VERSION "c2g-draft-1"

NS_ :

BS_:

BU_: MAXXECU

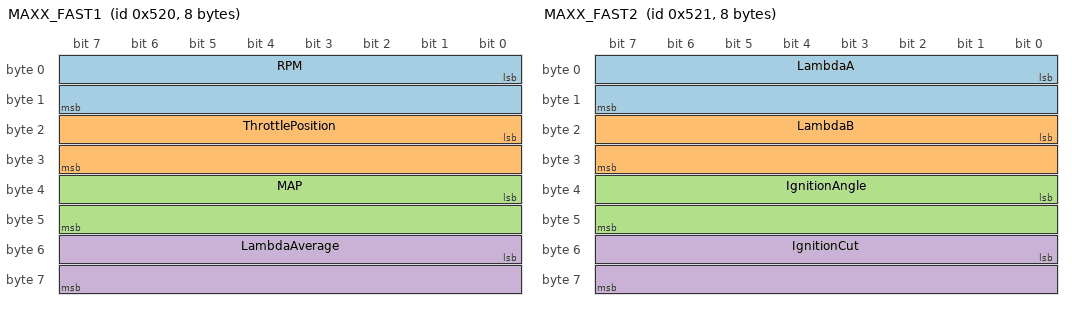
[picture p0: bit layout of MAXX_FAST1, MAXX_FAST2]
BO_ 1312 MAXX_FAST1: 8 MAXXECU
 SG_ RPM : 0|16@1- (1,0) [-32768|32767] "rpm" Vector__XXX
 SG_ ThrottlePosition : 16|16@1- (0.1,0) [-3276.8|3276.7] "%" Vector__XXX
 SG_ MAP : 32|16@1- (0.1,0) [-3276.8|3276.7] "kPa" Vector__XXX
 SG_ LambdaAverage : 48|16@1- (0.001,0) [-32.768|32.767] "lambda" Vector__XXX

BO_ 1313 MAXX_FAST2: 8 MAXXECU
 SG_ LambdaA : 0|16@1- (0.001,0) [-32.768|32.767] "lambda" Vector__XXX
 SG_ LambdaB : 16|16@1- (0.001,0) [-32.768|32.767] "lambda" Vector__XXX
 SG_ IgnitionAngle : 32|16@1- (0.1,0) [-3276.8|3276.7] "deg" Vector__XXX
 SG_ IgnitionCut : 48|16@1- (1,0) [-32768|32767] "%" Vector__XXX

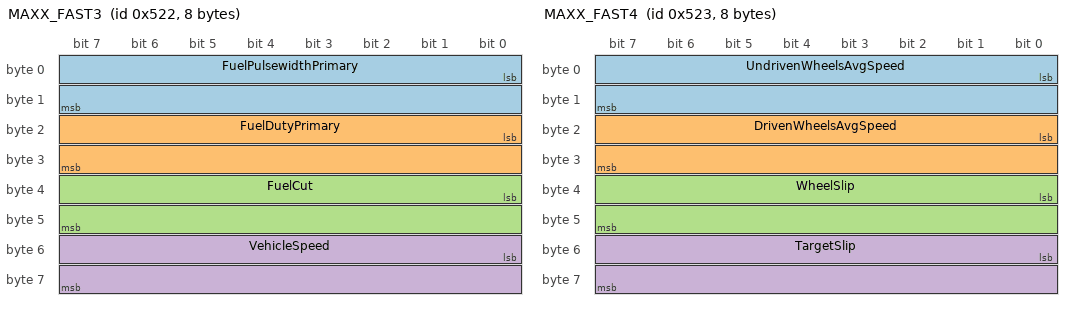
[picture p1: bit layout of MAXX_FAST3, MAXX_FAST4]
BO_ 1314 MAXX_FAST3: 8 MAXXECU
 SG_ FuelPulsewidthPrimary : 0|16@1- (0.01,0) [-327.68|327.67] "ms" Vector__XXX
 SG_ FuelDutyPrimary : 16|16@1- (0.1,0) [-3276.8|3276.7] "%" Vector__XXX
 SG_ FuelCut : 32|16@1- (1,0) [-32768|32767] "%" Vector__XXX
 SG_ VehicleSpeed : 48|16@1- (0.1,0) [-3276.8|3276.7] "km/h" Vector__XXX

BO_ 1315 MAXX_FAST4: 8 MAXXECU
 SG_ UndrivenWheelsAvgSpeed : 0|16@1- (0.1,0) [-3276.8|3276.7] "km/h" Vector__XXX
 SG_ DrivenWheelsAvgSpeed : 16|16@1- (0.1,0) [-3276.8|3276.7] "km/h" Vector__XXX
 SG_ WheelSlip : 32|16@1- (0.1,0) [-3276.8|3276.7] "%" Vector__XXX
 SG_ TargetSlip : 48|16@1- (0.1,0) [-3276.8|3276.7] "%" Vector__XXX

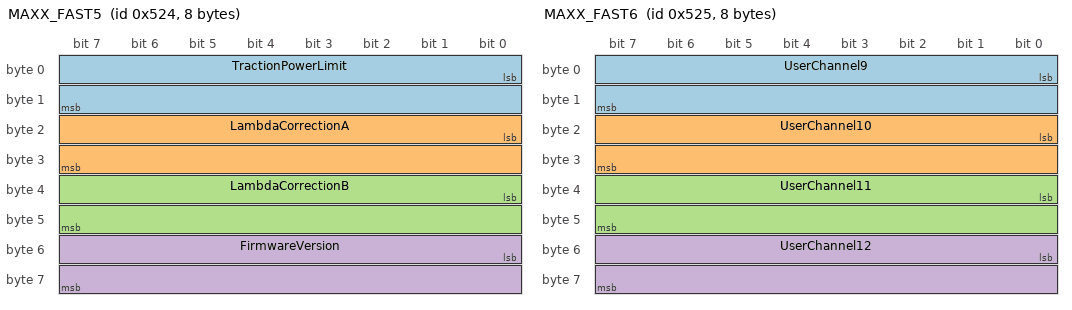
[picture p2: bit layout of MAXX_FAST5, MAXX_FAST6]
BO_ 1316 MAXX_FAST5: 8 MAXXECU
 SG_ TractionPowerLimit : 0|16@1- (0.1,0) [-3276.8|3276.7] "%" Vector__XXX
 SG_ LambdaCorrectionA : 16|16@1- (0.1,0) [-3276.8|3276.7] "%" Vector__XXX
 SG_ LambdaCorrectionB : 32|16@1- (0.1,0) [-3276.8|3276.7] "%" Vector__XXX
 SG_ FirmwareVersion : 48|16@1- (0.001,0) [-32.768|32.767] "" Vector__XXX

BO_ 1317 MAXX_FAST6: 8 MAXXECU
 SG_ UserChannel9 : 0|16@1- (0.1,0) [-3276.8|3276.7] "" Vector__XXX
 SG_ UserChannel10 : 16|16@1- (0.1,0) [-3276.8|3276.7] "" Vector__XXX
 SG_ UserChannel11 : 32|16@1- (0.1,0) [-3276.8|3276.7] "" Vector__XXX
 SG_ UserChannel12 : 48|16@1- (0.1,0) [-3276.8|3276.7] "" Vector__XXX

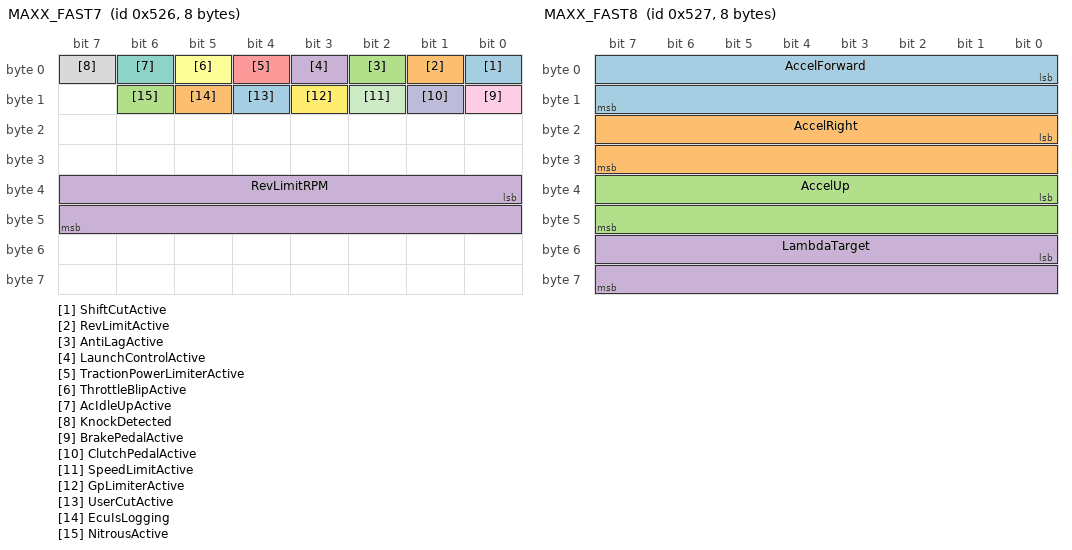
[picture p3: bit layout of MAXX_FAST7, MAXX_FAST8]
BO_ 1318 MAXX_FAST7: 8 MAXXECU
 SG_ ShiftCutActive : 0|1@1+ (1,0) [0|1] "" Vector__XXX
 SG_ RevLimitActive : 1|1@1+ (1,0) [0|1] "" Vector__XXX
 SG_ AntiLagActive : 2|1@1+ (1,0) [0|1] "" Vector__XXX
 SG_ LaunchControlActive : 3|1@1+ (1,0) [0|1] "" Vector__XXX
 SG_ TractionPowerLimiterActive : 4|1@1+ (1,0) [0|1] "" Vector__XXX
 SG_ ThrottleBlipActive : 5|1@1+ (1,0) [0|1] "" Vector__XXX
 SG_ AcIdleUpActive : 6|1@1+ (1,0) [0|1] "" Vector__XXX
 SG_ KnockDetected : 7|1@1+ (1,0) [0|1] "" Vector__XXX
 SG_ BrakePedalActive : 8|1@1+ (1,0) [0|1] "" Vector__XXX
 SG_ ClutchPedalActive : 9|1@1+ (1,0) [0|1] "" Vector__XXX
 SG_ SpeedLimitActive : 10|1@1+ (1,0) [0|1] "" Vector__XXX
 SG_ GpLimiterActive : 11|1@1+ (1,0) [0|1] "" Vector__XXX
 SG_ UserCutActive : 12|1@1+ (1,0) [0|1] "" Vector__XXX
 SG_ EcuIsLogging : 13|1@1+ (1,0) [0|1] "" Vector__XXX
 SG_ NitrousActive : 14|1@1+ (1,0) [0|1] "" Vector__XXX
 SG_ RevLimitRPM : 32|16@1- (1,0) [-32768|32767] "rpm" Vector__XXX

BO_ 1319 MAXX_FAST8: 8 MAXXECU
 SG_ AccelForward : 0|16@1- (0.01,0) [-327.68|327.67] "G" Vector__XXX
 SG_ AccelRight : 16|16@1- (0.01,0) [-327.68|327.67] "G" Vector__XXX
 SG_ AccelUp : 32|16@1- (0.01,0) [-327.68|327.67] "G" Vector__XXX
 SG_ LambdaTarget : 48|16@1- (0.001,0) [-32.768|32.767] "lambda" Vector__XXX

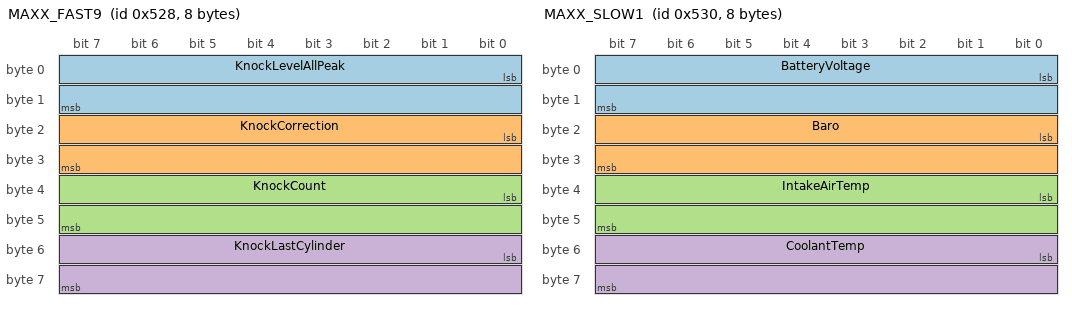
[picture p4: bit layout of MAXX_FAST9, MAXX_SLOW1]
BO_ 1320 MAXX_FAST9: 8 MAXXECU
 SG_ KnockLevelAllPeak : 0|16@1- (1,0) [-32768|32767] "" Vector__XXX
 SG_ KnockCorrection : 16|16@1- (0.1,0) [-3276.8|3276.7] "deg" Vector__XXX
 SG_ KnockCount : 32|16@1- (1,0) [-32768|32767] "" Vector__XXX
 SG_ KnockLastCylinder : 48|16@1- (1,0) [-32768|32767] "" Vector__XXX

BO_ 1328 MAXX_SLOW1: 8 MAXXECU
 SG_ BatteryVoltage : 0|16@1- (0.01,0) [-327.68|327.67] "V" Vector__XXX
 SG_ Baro : 16|16@1- (0.1,0) [-3276.8|3276.7] "kPa" Vector__XXX
 SG_ IntakeAirTemp : 32|16@1- (0.1,0) [-3276.8|3276.7] "C" Vector__XXX
 SG_ CoolantTemp : 48|16@1- (0.1,0) [-3276.8|3276.7] "C" Vector__XXX

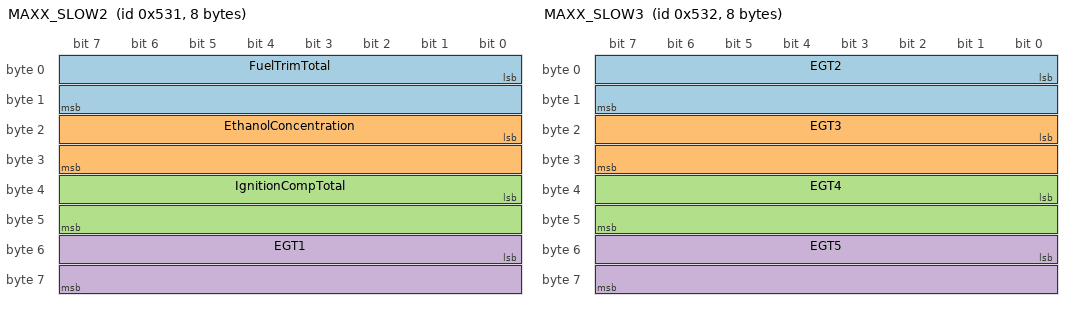
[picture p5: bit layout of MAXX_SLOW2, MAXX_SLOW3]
BO_ 1329 MAXX_SLOW2: 8 MAXXECU
 SG_ FuelTrimTotal : 0|16@1- (0.1,0) [-3276.8|3276.7] "%" Vector__XXX
 SG_ EthanolConcentration : 16|16@1- (0.1,0) [-3276.8|3276.7] "%" Vector__XXX
 SG_ IgnitionCompTotal : 32|16@1- (0.1,0) [-3276.8|3276.7] "deg" Vector__XXX
 SG_ EGT1 : 48|16@1- (1,0) [-32768|32767] "C" Vector__XXX

BO_ 1330 MAXX_SLOW3: 8 MAXXECU
 SG_ EGT2 : 0|16@1- (1,0) [-32768|32767] "C" Vector__XXX
 SG_ EGT3 : 16|16@1- (1,0) [-32768|32767] "C" Vector__XXX
 SG_ EGT4 : 32|16@1- (1,0) [-32768|32767] "C" Vector__XXX
 SG_ EGT5 : 48|16@1- (1,0) [-32768|32767] "C" Vector__XXX

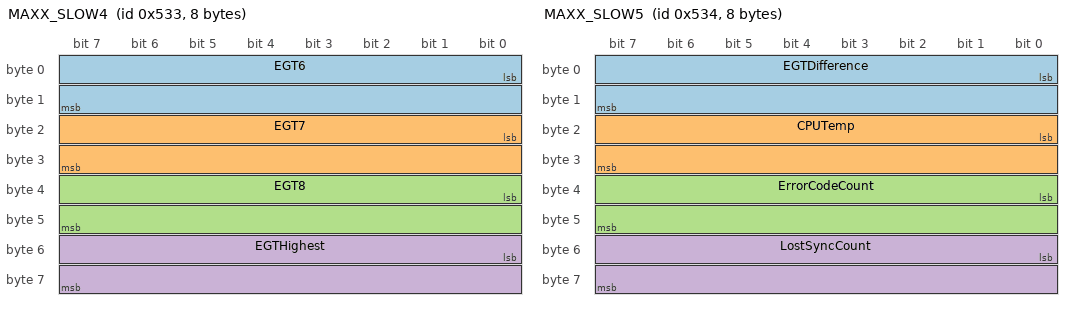
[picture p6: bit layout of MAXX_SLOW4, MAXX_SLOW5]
BO_ 1331 MAXX_SLOW4: 8 MAXXECU
 SG_ EGT6 : 0|16@1- (1,0) [-32768|32767] "C" Vector__XXX
 SG_ EGT7 : 16|16@1- (1,0) [-32768|32767] "C" Vector__XXX
 SG_ EGT8 : 32|16@1- (1,0) [-32768|32767] "C" Vector__XXX
 SG_ EGTHighest : 48|16@1- (1,0) [-32768|32767] "C" Vector__XXX

BO_ 1332 MAXX_SLOW5: 8 MAXXECU
 SG_ EGTDifference : 0|16@1- (1,0) [-32768|32767] "C" Vector__XXX
 SG_ CPUTemp : 16|16@1- (1,0) [-32768|32767] "C" Vector__XXX
 SG_ ErrorCodeCount : 32|16@1- (1,0) [-32768|32767] "" Vector__XXX
 SG_ LostSyncCount : 48|16@1- (1,0) [-32768|32767] "" Vector__XXX

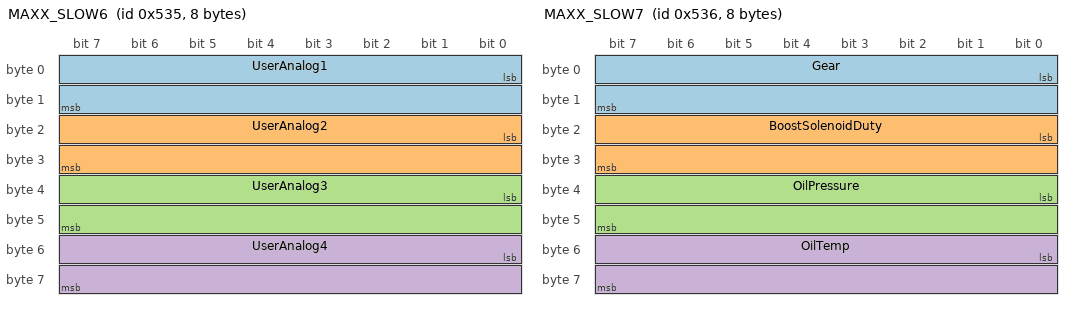
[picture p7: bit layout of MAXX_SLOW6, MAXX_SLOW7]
BO_ 1333 MAXX_SLOW6: 8 MAXXECU
 SG_ UserAnalog1 : 0|16@1- (0.1,0) [-3276.8|3276.7] "" Vector__XXX
 SG_ UserAnalog2 : 16|16@1- (0.1,0) [-3276.8|3276.7] "" Vector__XXX
 SG_ UserAnalog3 : 32|16@1- (0.1,0) [-3276.8|3276.7] "" Vector__XXX
 SG_ UserAnalog4 : 48|16@1- (0.1,0) [-3276.8|3276.7] "" Vector__XXX

BO_ 1334 MAXX_SLOW7: 8 MAXXECU
 SG_ Gear : 0|16@1- (1,0) [-32768|32767] "" Vector__XXX
 SG_ BoostSolenoidDuty : 16|16@1- (0.1,0) [-3276.8|3276.7] "%" Vector__XXX
 SG_ OilPressure : 32|16@1- (0.1,0) [-3276.8|3276.7] "kPa" Vector__XXX
 SG_ OilTemp : 48|16@1- (0.1,0) [-3276.8|3276.7] "C" Vector__XXX

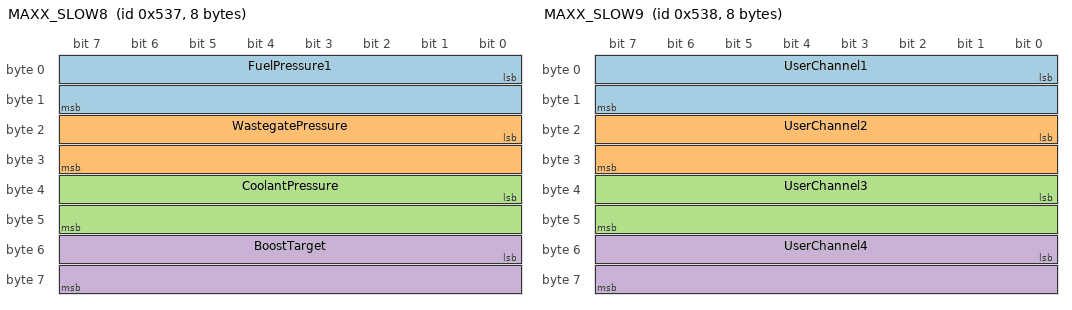
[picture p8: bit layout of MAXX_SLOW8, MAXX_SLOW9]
BO_ 1335 MAXX_SLOW8: 8 MAXXECU
 SG_ FuelPressure1 : 0|16@1- (0.1,0) [-3276.8|3276.7] "kPa" Vector__XXX
 SG_ WastegatePressure : 16|16@1- (0.1,0) [-3276.8|3276.7] "kPa" Vector__XXX
 SG_ CoolantPressure : 32|16@1- (0.1,0) [-3276.8|3276.7] "kPa" Vector__XXX
 SG_ BoostTarget : 48|16@1- (0.1,0) [-3276.8|3276.7] "kPa" Vector__XXX

BO_ 1336 MAXX_SLOW9: 8 MAXXECU
 SG_ UserChannel1 : 0|16@1- (0.1,0) [-3276.8|3276.7] "" Vector__XXX
 SG_ UserChannel2 : 16|16@1- (0.1,0) [-3276.8|3276.7] "" Vector__XXX
 SG_ UserChannel3 : 32|16@1- (0.1,0) [-3276.8|3276.7] "" Vector__XXX
 SG_ UserChannel4 : 48|16@1- (0.1,0) [-3276.8|3276.7] "" Vector__XXX

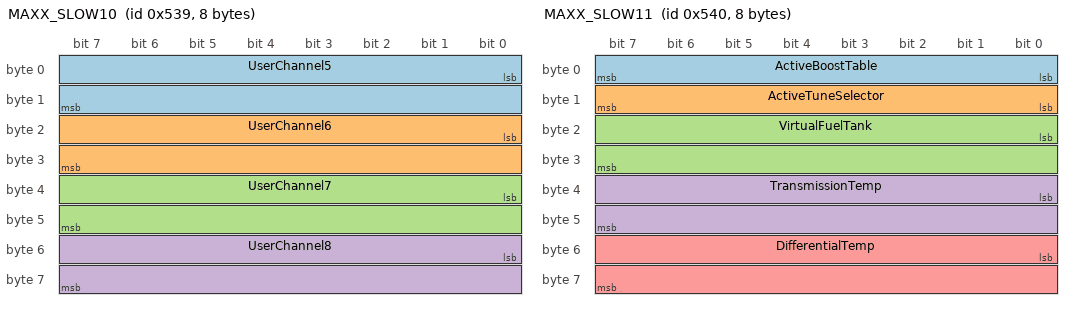
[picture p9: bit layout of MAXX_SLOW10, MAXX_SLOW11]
BO_ 1337 MAXX_SLOW10: 8 MAXXECU
 SG_ UserChannel5 : 0|16@1- (0.1,0) [-3276.8|3276.7] "" Vector__XXX
 SG_ UserChannel6 : 16|16@1- (0.1,0) [-3276.8|3276.7] "" Vector__XXX
 SG_ UserChannel7 : 32|16@1- (0.1,0) [-3276.8|3276.7] "" Vector__XXX
 SG_ UserChannel8 : 48|16@1- (0.1,0) [-3276.8|3276.7] "" Vector__XXX

BO_ 1344 MAXX_SLOW11: 8 MAXXECU
 SG_ ActiveBoostTable : 0|8@1+ (1,0) [0|255] "" Vector__XXX
 SG_ ActiveTuneSelector : 8|8@1+ (1,0) [0|255] "" Vector__XXX
 SG_ VirtualFuelTank : 16|16@1- (0.1,0) [-3276.8|3276.7] "L" Vector__XXX
 SG_ TransmissionTemp : 32|16@1- (0.1,0) [-3276.8|3276.7] "C" Vector__XXX
 SG_ DifferentialTemp : 48|16@1- (0.1,0) [-3276.8|3276.7] "C" Vector__XXX

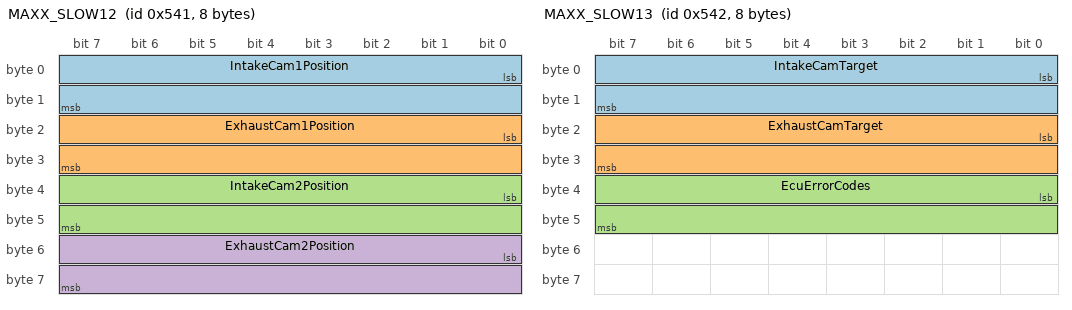
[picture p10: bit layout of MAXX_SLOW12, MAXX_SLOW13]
BO_ 1345 MAXX_SLOW12: 8 MAXXECU
 SG_ IntakeCam1Position : 0|16@1- (0.1,0) [-3276.8|3276.7] "deg" Vector__XXX
 SG_ ExhaustCam1Position : 16|16@1- (0.1,0) [-3276.8|3276.7] "deg" Vector__XXX
 SG_ IntakeCam2Position : 32|16@1- (0.1,0) [-3276.8|3276.7] "deg" Vector__XXX
 SG_ ExhaustCam2Position : 48|16@1- (0.1,0) [-3276.8|3276.7] "deg" Vector__XXX

BO_ 1346 MAXX_SLOW13: 8 MAXXECU
 SG_ IntakeCamTarget : 0|16@1- (0.1,0) [-3276.8|3276.7] "deg" Vector__XXX
 SG_ ExhaustCamTarget : 16|16@1- (0.1,0) [-3276.8|3276.7] "deg" Vector__XXX
 SG_ EcuErrorCodes : 32|16@1+ (1,0) [0|65535] "" Vector__XXX

CM_ "DRAFT can2gauge DBC: MaxxECU Default CAN protocol 1.2 + 1.3 (base 0x520, movable with 'DefaultCANProtocol ID Offset', fw 1.149+). Written from the published webhelp layout; MaxxECU's own DBC (TT-Speed, no licence stated) was only read for cross-checking. All values int16 per the webhelp.";
CM_ BO_ 1312 "Source: maxxecu.com webhelp can-default_maxxecu_protocol. v1.2.";
CM_ SG_ 1312 MAP "Absolute kPa (gauge 'map' is mbar: x10). Boost = MAP - baro (0x530) stays in code.";
CM_ BO_ 1313 "Source: maxxecu.com webhelp can-default_maxxecu_protocol. v1.2.";
CM_ BO_ 1314 "Source: maxxecu.com webhelp can-default_maxxecu_protocol. v1.2.";
CM_ BO_ 1315 "Source: maxxecu.com webhelp can-default_maxxecu_protocol. v1.2.";
CM_ BO_ 1316 "Source: maxxecu.com webhelp can-default_maxxecu_protocol. v1.2.";
CM_ SG_ 1316 FirmwareVersion "Webhelp scale 0.001; MaxxECU's own v1.3 DBC says 0.01 - UNVERIFIED which. Constant while running: useful fingerprint.";
CM_ BO_ 1317 "Source: maxxecu.com webhelp can-default_maxxecu_protocol. v1.3, fw 1.135+.";
CM_ BO_ 1318 "Source: maxxecu.com webhelp can-default_maxxecu_protocol. v1.3, fw 1.135+.";
CM_ SG_ 1318 KnockDetected "Held 250 ms after a knock (MaxxECU DBC comment).";
CM_ BO_ 1319 "Source: maxxecu.com webhelp can-default_maxxecu_protocol. v1.3, fw 1.135+.";
CM_ BO_ 1320 "Source: maxxecu.com webhelp can-default_maxxecu_protocol. v1.3, fw 1.135+.";
CM_ SG_ 1320 KnockCorrection "Sign convention (retard positive or negative) not stated - UNVERIFIED.";
CM_ BO_ 1328 "Source: maxxecu.com webhelp can-default_maxxecu_protocol. v1.2.";
CM_ SG_ 1328 Baro "Fingerprint: raw ~950-1050 at sea level.";
CM_ BO_ 1329 "Source: maxxecu.com webhelp can-default_maxxecu_protocol. v1.2.";
CM_ SG_ 1329 EthanolConcentration "Webhelp: outputs 85 % with no sensor or a sensor error. MaxxECU's own DBC comment says zero - UNVERIFIED which (firmware dependent?).";
CM_ SG_ 1329 EGT1 "All EGTs are sent even for unconfigured sensors.";
CM_ BO_ 1330 "Source: maxxecu.com webhelp can-default_maxxecu_protocol. v1.2.";
CM_ BO_ 1331 "Source: maxxecu.com webhelp can-default_maxxecu_protocol. v1.2.";
CM_ BO_ 1332 "Source: maxxecu.com webhelp can-default_maxxecu_protocol. v1.2.";
CM_ BO_ 1333 "Source: maxxecu.com webhelp can-default_maxxecu_protocol. v1.2, fw 1.79+.";
CM_ BO_ 1334 "Source: maxxecu.com webhelp can-default_maxxecu_protocol. Bytes 0-3 v1.2 (fw 1.79+), bytes 4-7 v1.3 (fw 1.135+; nothing sent there in 1.2).";
CM_ SG_ 1334 Gear "Encoding of reverse / neutral not documented - UNVERIFIED (0 assumed neutral).";
CM_ SG_ 1334 BoostSolenoidDuty "Webhelp table says v1.2; its changelog says 0x536 bytes 2-3 were spare in 1.2 - UNVERIFIED.";
CM_ SG_ 1334 OilPressure "kPa (gauge 'oilPressure' is bar: /100). Absolute or gauge not stated - UNVERIFIED.";
CM_ BO_ 1335 "Source: maxxecu.com webhelp can-default_maxxecu_protocol. v1.3, fw 1.135+.";
CM_ SG_ 1335 FuelPressure1 "kPa (gauge 'fuelPressure' is bar: /100). Absolute or gauge not stated - UNVERIFIED.";
CM_ BO_ 1336 "Source: maxxecu.com webhelp can-default_maxxecu_protocol. v1.3, fw 1.135+.";
CM_ BO_ 1337 "Source: maxxecu.com webhelp can-default_maxxecu_protocol. v1.3, fw 1.135+.";
CM_ BO_ 1344 "Source: maxxecu.com webhelp can-default_maxxecu_protocol. v1.3, fw 1.135+. MaxxECU warns 0x540 collides with VAG DSG: use 1.2 (or move the offset) on DSG cars.";
CM_ BO_ 1345 "Source: maxxecu.com webhelp can-default_maxxecu_protocol. v1.3, fw 1.135+.";
CM_ BO_ 1346 "Source: maxxecu.com webhelp can-default_maxxecu_protocol. v1.3, fw 1.135+.";
CM_ SG_ 1346 EcuErrorCodes "uint16, fw 1.149+, rotates through stored codes, 0x0000 = none.";
BA_DEF_ SG_ "GaugeKey" STRING ;
BA_DEF_ "GaugeRelocatable" INT 0 1;
BA_DEF_ "GaugeBusSpeed" INT 0 1000000;
BA_DEF_ BO_ "GenMsgCycleTime" INT 0 65535;
BA_DEF_DEF_ "GaugeKey" "";
BA_DEF_DEF_ "GaugeRelocatable" 0;
BA_DEF_DEF_ "GaugeBusSpeed" 500000;
BA_DEF_DEF_ "GenMsgCycleTime" 0;
BA_ "GaugeRelocatable" 1;
BA_ "GenMsgCycleTime" BO_ 1312 20;
BA_ "GenMsgCycleTime" BO_ 1313 20;
BA_ "GenMsgCycleTime" BO_ 1314 20;
BA_ "GenMsgCycleTime" BO_ 1315 20;
BA_ "GenMsgCycleTime" BO_ 1316 20;
BA_ "GenMsgCycleTime" BO_ 1317 20;
BA_ "GenMsgCycleTime" BO_ 1318 20;
BA_ "GenMsgCycleTime" BO_ 1319 20;
BA_ "GenMsgCycleTime" BO_ 1320 20;
BA_ "GenMsgCycleTime" BO_ 1328 100;
BA_ "GenMsgCycleTime" BO_ 1329 100;
BA_ "GenMsgCycleTime" BO_ 1330 100;
BA_ "GenMsgCycleTime" BO_ 1331 100;
BA_ "GenMsgCycleTime" BO_ 1332 100;
BA_ "GenMsgCycleTime" BO_ 1333 100;
BA_ "GenMsgCycleTime" BO_ 1334 100;
BA_ "GenMsgCycleTime" BO_ 1335 100;
BA_ "GenMsgCycleTime" BO_ 1336 100;
BA_ "GenMsgCycleTime" BO_ 1337 100;
BA_ "GenMsgCycleTime" BO_ 1344 100;
BA_ "GenMsgCycleTime" BO_ 1345 100;
BA_ "GenMsgCycleTime" BO_ 1346 100;
BA_ "GaugeKey" SG_ 1312 RPM "rpm";
BA_ "GaugeKey" SG_ 1312 ThrottlePosition "throttle";
BA_ "GaugeKey" SG_ 1312 MAP "map";
BA_ "GaugeKey" SG_ 1312 LambdaAverage "lambda";
BA_ "GaugeKey" SG_ 1313 IgnitionAngle "timing";
BA_ "GaugeKey" SG_ 1314 FuelDutyPrimary "injDuty";
BA_ "GaugeKey" SG_ 1314 VehicleSpeed "speed";
BA_ "GaugeKey" SG_ 1319 LambdaTarget "lambdaTarget";
BA_ "GaugeKey" SG_ 1320 KnockCorrection "knockRetard";
BA_ "GaugeKey" SG_ 1328 BatteryVoltage "batt";
BA_ "GaugeKey" SG_ 1328 IntakeAirTemp "iat";
BA_ "GaugeKey" SG_ 1328 CoolantTemp "coolant";
BA_ "GaugeKey" SG_ 1329 EthanolConcentration "ethanol";
BA_ "GaugeKey" SG_ 1331 EGTHighest "egt";
BA_ "GaugeKey" SG_ 1334 Gear "gear";
BA_ "GaugeKey" SG_ 1334 OilPressure "oilPressure";
BA_ "GaugeKey" SG_ 1334 OilTemp "oiltemp";
BA_ "GaugeKey" SG_ 1335 FuelPressure1 "fuelPressure";
BA_ "GaugeKey" SG_ 1344 TransmissionTemp "gboxTemp";
VAL_ 1334 Gear 0 "N" ;
